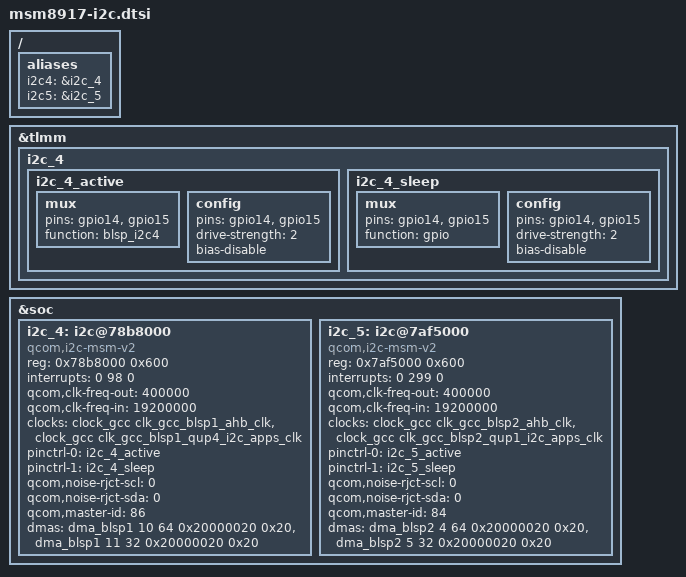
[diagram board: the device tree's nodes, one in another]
&tlmm {
	i2c_4 {
		i2c_4_active: i2c_4_active {
			/* active state */
			mux {
				pins = "gpio14", "gpio15";
				function = "blsp_i2c4";
		};

		config {
				pins = "gpio14", "gpio15";
				drive-strength = <2>;
				bias-disable;
			};
		};

		i2c_4_sleep: i2c_4_sleep {
			/* suspended state */
			mux {
				pins = "gpio14", "gpio15";
				function = "gpio";
			};

			config {
				pins = "gpio14", "gpio15";
				drive-strength = <2>;
				bias-disable;
			};
		};
	};
};

/ {
	aliases {
		i2c4 = &i2c_4;
		i2c5 = &i2c_5;
	};
};

&soc {
	i2c_4: i2c@78b8000 { /* BLSP1 QUP4 */
		compatible = "qcom,i2c-msm-v2";
		#address-cells = <1>;
		#size-cells = <0>;
		reg-names = "qup_phys_addr";
		reg = <0x78b8000 0x600>;
		interrupt-names = "qup_irq";
		interrupts = <0 98 0>;
		qcom,clk-freq-out = <400000>;
		qcom,clk-freq-in  = <19200000>;
		clock-names = "iface_clk", "core_clk";
		clocks = <&clock_gcc clk_gcc_blsp1_ahb_clk>,
			<&clock_gcc clk_gcc_blsp1_qup4_i2c_apps_clk>;

		pinctrl-names = "i2c_active", "i2c_sleep";
		pinctrl-0 = <&i2c_4_active>;
		pinctrl-1 = <&i2c_4_sleep>;
		qcom,noise-rjct-scl = <0>;
		qcom,noise-rjct-sda = <0>;
		qcom,master-id = <86>;
		dmas = <&dma_blsp1 10 64 0x20000020 0x20>,
			<&dma_blsp1 11 32 0x20000020 0x20>;
		dma-names = "tx", "rx";
	};

	i2c_5: i2c@7af5000 { /* BLSP2 QUP1 */
		status = "okay";
		compatible = "qcom,i2c-msm-v2";
		#address-cells = <1>;
		#size-cells = <0>;
		reg-names = "qup_phys_addr";
		reg = <0x7af5000 0x600>;
		interrupt-names = "qup_irq";
		interrupts = <0 299 0>;
		qcom,clk-freq-out = <400000>;
		qcom,clk-freq-in  = <19200000>;
		clock-names = "iface_clk", "core_clk";
		clocks = <&clock_gcc clk_gcc_blsp2_ahb_clk>,
			<&clock_gcc clk_gcc_blsp2_qup1_i2c_apps_clk>;

		pinctrl-names = "i2c_active", "i2c_sleep";
		pinctrl-0 = <&i2c_5_active>;
		pinctrl-1 = <&i2c_5_sleep>;
		qcom,noise-rjct-scl = <0>;
		qcom,noise-rjct-sda = <0>;
		qcom,master-id = <84>;
		dmas = <&dma_blsp2 4 64 0x20000020 0x20>,
			<&dma_blsp2 5 32 0x20000020 0x20>;
		dma-names = "tx", "rx";
	};
};
